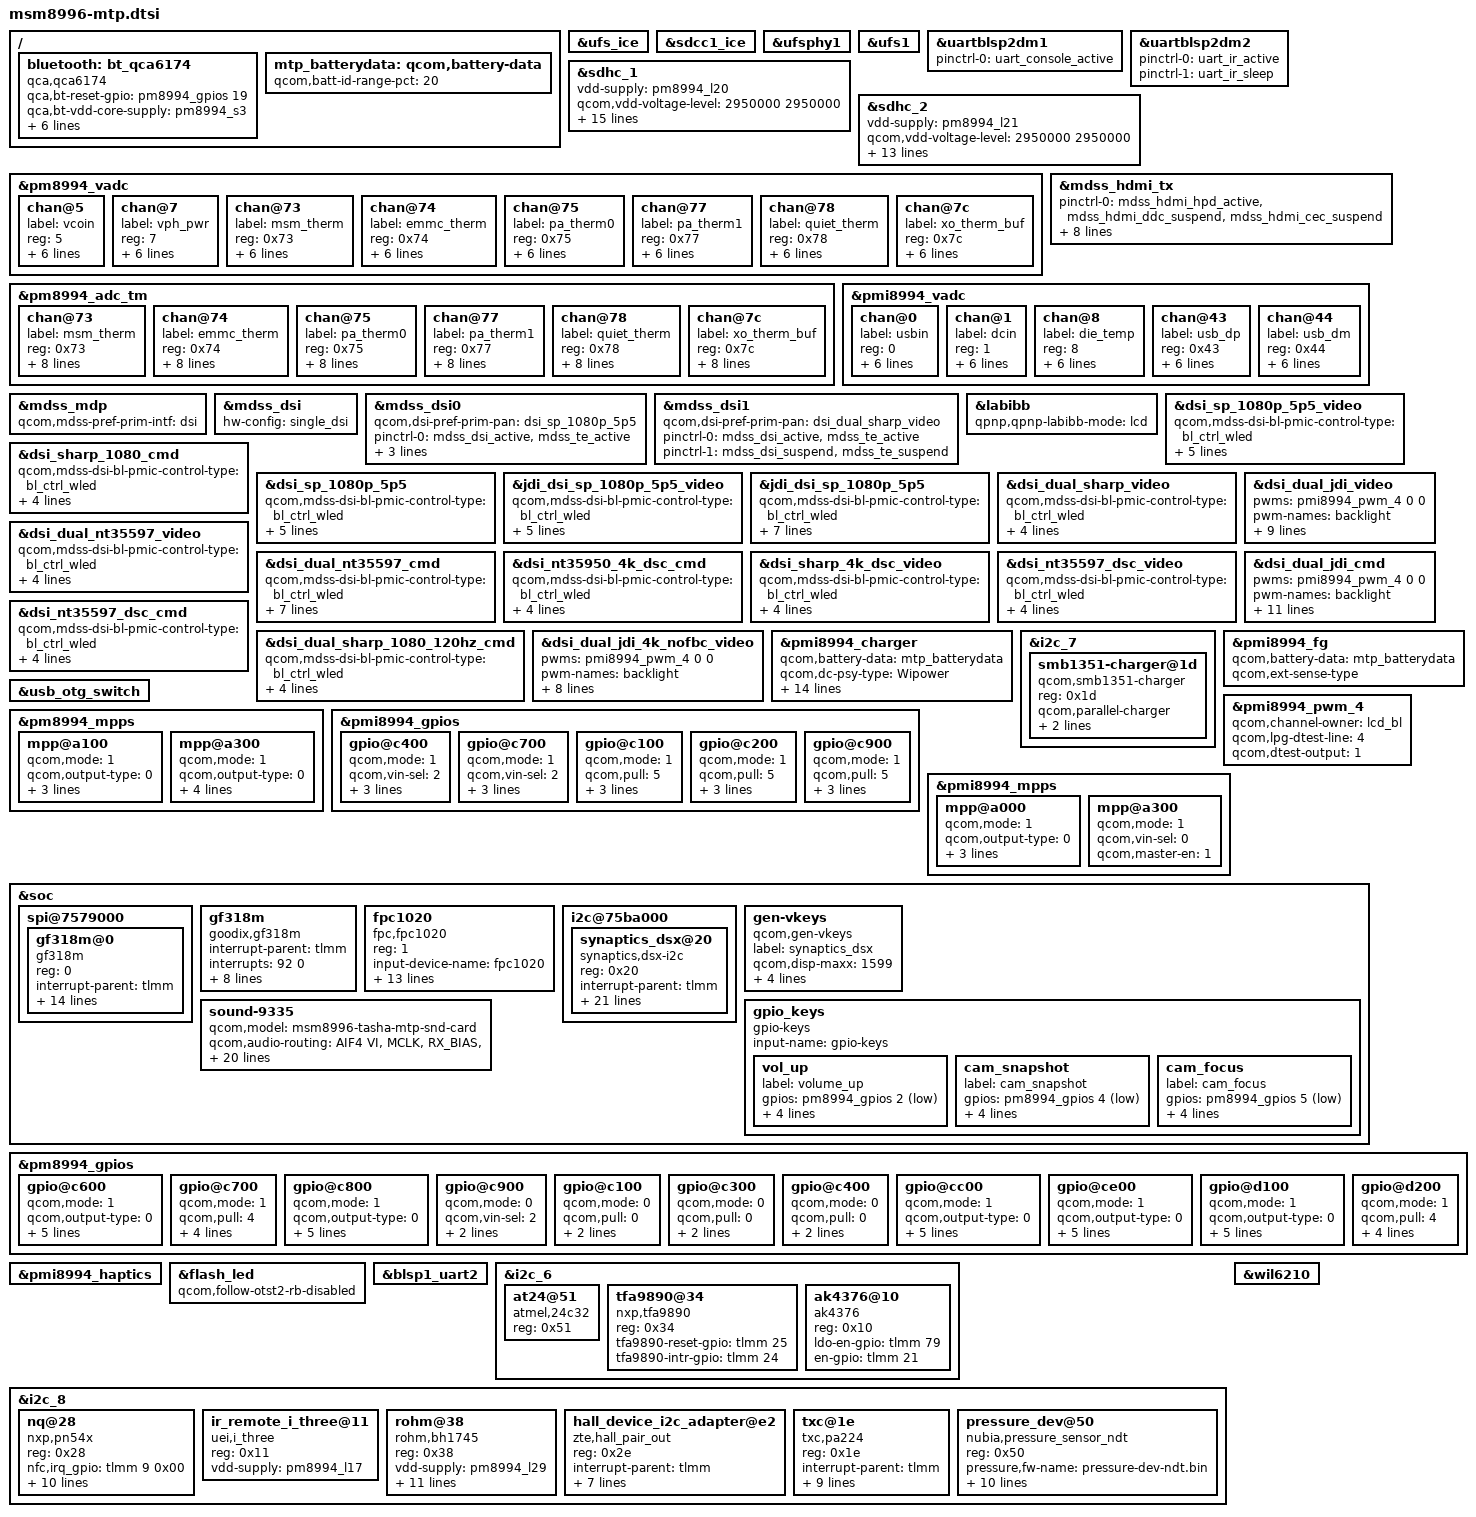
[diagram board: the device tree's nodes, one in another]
/* Copyright (c) 2015-2016, The Linux Foundation. All rights reserved.
 *
 * This program is free software; you can redistribute it and/or modify
 * it under the terms of the GNU General Public License version 2 and
 * only version 2 as published by the Free Software Foundation.
 *
 * This program is distributed in the hope that it will be useful,
 * but WITHOUT ANY WARRANTY; without even the implied warranty of
 * MERCHANTABILITY or FITNESS FOR A PARTICULAR PURPOSE.  See the
 * GNU General Public License for more details.
 */

#include "msm8996-pinctrl.dtsi"
#include "msm8996-camera-sensor-mtp.dtsi"
#include "msm8996-mtp-typec-ctl.dtsi"

/ {
	bluetooth: bt_qca6174 {
		compatible = "qca,qca6174";
		qca,bt-reset-gpio = <&pm8994_gpios 19 0>; /* BT_EN */
		qca,bt-vdd-core-supply = <&pm8994_s3>;
		qca,bt-vdd-pa-supply = <&rome_vreg>;
		qca,bt-vdd-io-supply = <&pm8994_s4>;
		qca,bt-vdd-xtal-supply = <&pm8994_l30>;
		qca,bt-chip-pwd-voltage-level = <1300000 1300000>;
		qca,bt-vdd-io-voltage-level = <1800000 1800000>;
		qca,bt-vdd-xtal-voltage-level = <1800000 1800000>;
	};
};

&ufs_ice {
        status = "ok";
};

&sdcc1_ice {
        status = "ok";
};

&ufsphy1 {
	status = "ok";
};

&ufs1 {
	status = "ok";
};

&uartblsp2dm1 {
	status = "ok";
	pinctrl-names = "default";
	pinctrl-0 = <&uart_console_active>;
};
&uartblsp2dm2 {
	status = "ok";
	pinctrl-names = "default","sleep";
	pinctrl-0 = <&uart_ir_active>;
	pinctrl-1 = <&uart_ir_sleep>;
};
&sdhc_1 {
	vdd-supply = <&pm8994_l20>;
	qcom,vdd-voltage-level = <2950000 2950000>;
	qcom,vdd-current-level = <200 570000>;

	vdd-io-supply = <&pm8994_s4>;
	qcom,vdd-io-always-on;
	qcom,vdd-io-voltage-level = <1800000 1800000>;
	qcom,vdd-io-current-level = <110 325000>;

	pinctrl-names = "active", "sleep";
	pinctrl-0 = <&sdc1_clk_on &sdc1_cmd_on &sdc1_data_on &sdc1_rclk_on>;
	pinctrl-1 = <&sdc1_clk_off &sdc1_cmd_off &sdc1_data_off &sdc1_rclk_off>;

	qcom,clk-rates = <400000 20000000 25000000 50000000 96000000 192000000 384000000>;
	qcom,ice-clk-rates = <300000000 150000000>;
	qcom,nonremovable;
	qcom,bus-speed-mode = "HS400_1p8v", "HS200_1p8v", "DDR_1p8v";

	status = "ok";
};

&sdhc_2 {
	vdd-supply = <&pm8994_l21>;
	qcom,vdd-voltage-level = <2950000 2950000>;
	qcom,vdd-current-level = <200 800000>;

	vdd-io-supply = <&pm8994_l13>;
	qcom,vdd-io-voltage-level = <1800000 2950000>;
	qcom,vdd-io-current-level = <200 22000>;

	pinctrl-names = "active", "sleep";
	pinctrl-0 = <&sdc2_clk_on  &sdc2_cmd_on &sdc2_data_on &sdc2_cd_on>;
	pinctrl-1 = <&sdc2_clk_off &sdc2_cmd_off &sdc2_data_off &sdc2_cd_off>;

	qcom,clk-rates = <400000 20000000 25000000 50000000 100000000 200000000>;
	qcom,bus-speed-mode = "SDR12", "SDR25", "SDR50", "DDR50", "SDR104";

	cd-gpios = <&tlmm 95 0x0>;

	status = "ok";
};

&pm8994_vadc {
	chan@5 {
		label = "vcoin";
		reg = <5>;
		qcom,decimation = <0>;
		qcom,pre-div-channel-scaling = <1>;
		qcom,calibration-type = "absolute";
		qcom,scale-function = <0>;
		qcom,hw-settle-time = <0>;
		qcom,fast-avg-setup = <0>;
	};

	chan@7 {
		label = "vph_pwr";
		reg = <7>;
		qcom,decimation = <0>;
		qcom,pre-div-channel-scaling = <1>;
		qcom,calibration-type = "absolute";
		qcom,scale-function = <0>;
		qcom,hw-settle-time = <0>;
		qcom,fast-avg-setup = <0>;
	};

	chan@73 {
		label = "msm_therm";
		reg = <0x73>;
		qcom,decimation = <0>;
		qcom,pre-div-channel-scaling = <0>;
		qcom,calibration-type = "ratiometric";
		qcom,scale-function = <2>;
		qcom,hw-settle-time = <2>;
		qcom,fast-avg-setup = <0>;
	};

	chan@74 {
		label = "emmc_therm";
		reg = <0x74>;
		qcom,decimation = <0>;
		qcom,pre-div-channel-scaling = <0>;
		qcom,calibration-type = "ratiometric";
		qcom,scale-function = <2>;
		qcom,hw-settle-time = <2>;
		qcom,fast-avg-setup = <0>;
	};

	chan@75 {
		label = "pa_therm0";
		reg = <0x75>;
		qcom,decimation = <0>;
		qcom,pre-div-channel-scaling = <0>;
		qcom,calibration-type = "ratiometric";
		qcom,scale-function = <2>;
		qcom,hw-settle-time = <2>;
		qcom,fast-avg-setup = <0>;
	};

	chan@77 {
		label = "pa_therm1";
		reg = <0x77>;
		qcom,decimation = <0>;
		qcom,pre-div-channel-scaling = <0>;
		qcom,calibration-type = "ratiometric";
		qcom,scale-function = <2>;
		qcom,hw-settle-time = <2>;
		qcom,fast-avg-setup = <0>;
	};

	chan@78 {
		label = "quiet_therm";
		reg = <0x78>;
		qcom,decimation = <0>;
		qcom,pre-div-channel-scaling = <0>;
		qcom,calibration-type = "ratiometric";
		qcom,scale-function = <2>;
		qcom,hw-settle-time = <2>;
		qcom,fast-avg-setup = <0>;
	};

	chan@7c {
		label = "xo_therm_buf";
		reg = <0x7c>;
		qcom,decimation = <0>;
		qcom,pre-div-channel-scaling = <0>;
		qcom,calibration-type = "ratiometric";
		qcom,scale-function = <4>;
		qcom,hw-settle-time = <2>;
		qcom,fast-avg-setup = <0>;
	};

	chan@7c {
		label = "xo_therm_buf";
		reg = <0x7c>;
		qcom,decimation = <0>;
		qcom,pre-div-channel-scaling = <0>;
		qcom,calibration-type = "ratiometric";
		qcom,scale-function = <4>;
		qcom,hw-settle-time = <2>;
		qcom,fast-avg-setup = <0>;
	};
};

&pm8994_adc_tm {
	chan@73 {
		label = "msm_therm";
		reg = <0x73>;
		qcom,decimation = <0>;
		qcom,pre-div-channel-scaling = <0>;
		qcom,calibration-type = "ratiometric";
		qcom,scale-function = <2>;
		qcom,hw-settle-time = <2>;
		qcom,fast-avg-setup = <0>;
		qcom,btm-channel-number = <0x48>;
		qcom,thermal-node;
	};

	chan@74 {
		label = "emmc_therm";
		reg = <0x74>;
		qcom,decimation = <0>;
		qcom,pre-div-channel-scaling = <0>;
		qcom,calibration-type = "ratiometric";
		qcom,scale-function = <2>;
		qcom,hw-settle-time = <2>;
		qcom,fast-avg-setup = <0>;
		qcom,btm-channel-number = <0x68>;
		qcom,thermal-node;
	};

	chan@75 {
		label = "pa_therm0";
		reg = <0x75>;
		qcom,decimation = <0>;
		qcom,pre-div-channel-scaling = <0>;
		qcom,calibration-type = "ratiometric";
		qcom,scale-function = <2>;
		qcom,hw-settle-time = <2>;
		qcom,fast-avg-setup = <0>;
		qcom,btm-channel-number = <0x70>;
		qcom,thermal-node;
	};

	chan@77 {
		label = "pa_therm1";
		reg = <0x77>;
		qcom,decimation = <0>;
		qcom,pre-div-channel-scaling = <0>;
		qcom,calibration-type = "ratiometric";
		qcom,scale-function = <2>;
		qcom,hw-settle-time = <2>;
		qcom,fast-avg-setup = <0>;
		qcom,btm-channel-number = <0x78>;
		qcom,thermal-node;
	};

	chan@78 {
		label = "quiet_therm";
		reg = <0x78>;
		qcom,decimation = <0>;
		qcom,pre-div-channel-scaling = <0>;
		qcom,calibration-type = "ratiometric";
		qcom,scale-function = <2>;
		qcom,hw-settle-time = <2>;
		qcom,fast-avg-setup = <0>;
		qcom,btm-channel-number = <0x80>;
		qcom,thermal-node;
	};

	chan@7c {
		label = "xo_therm_buf";
		reg = <0x7c>;
		qcom,decimation = <0>;
		qcom,pre-div-channel-scaling = <0>;
		qcom,calibration-type = "ratiometric";
		qcom,scale-function = <4>;
		qcom,hw-settle-time = <2>;
		qcom,fast-avg-setup = <0>;
		qcom,btm-channel-number = <0x88>;
		qcom,thermal-node;
	};
};

&mdss_hdmi_tx {
	pinctrl-names = "hdmi_hpd_active", "hdmi_ddc_active", "hdmi_cec_active",
				"hdmi_active", "hdmi_sleep";
	pinctrl-0 = <&mdss_hdmi_hpd_active &mdss_hdmi_ddc_suspend
						&mdss_hdmi_cec_suspend>;
	pinctrl-1 = <&mdss_hdmi_hpd_active &mdss_hdmi_ddc_active
						&mdss_hdmi_cec_suspend>;
	pinctrl-2 = <&mdss_hdmi_hpd_active &mdss_hdmi_cec_active
						&mdss_hdmi_ddc_suspend>;
	pinctrl-3 = <&mdss_hdmi_hpd_active &mdss_hdmi_ddc_active
						&mdss_hdmi_cec_active>;
	pinctrl-4 = <&mdss_hdmi_hpd_suspend &mdss_hdmi_ddc_suspend
						&mdss_hdmi_cec_suspend>;
};

&pmi8994_vadc {
	chan@0 {
		label = "usbin";
		reg = <0>;
		qcom,decimation = <0>;
		qcom,pre-div-channel-scaling = <4>;
		qcom,calibration-type = "absolute";
		qcom,scale-function = <0>;
		qcom,hw-settle-time = <0>;
		qcom,fast-avg-setup = <0>;
	};

	chan@1 {
		label = "dcin";
		reg = <1>;
		qcom,decimation = <0>;
		qcom,pre-div-channel-scaling = <4>;
		qcom,calibration-type = "absolute";
		qcom,scale-function = <0>;
		qcom,hw-settle-time = <0>;
		qcom,fast-avg-setup = <0>;
	};

	/*CONFIG_ZTEMT_MSM8996_CHARGER*/
	chan@8 {
		label = "die_temp";
		reg = <8>;
		qcom,decimation = <0>;
		qcom,pre-div-channel-scaling = <0>;
		qcom,calibration-type = "absolute";
		qcom,scale-function = <3>;
		qcom,hw-settle-time = <0>;
		qcom,fast-avg-setup = <0>;
	};

	chan@43 {
		label = "usb_dp";
		reg = <0x43>;
		qcom,decimation = <0>;
		qcom,pre-div-channel-scaling = <1>;
		qcom,calibration-type = "absolute";
		qcom,scale-function = <0>;
		qcom,hw-settle-time = <0>;
		qcom,fast-avg-setup = <0>;
	};

	chan@44 {
		label = "usb_dm";
		reg = <0x44>;
		qcom,decimation = <0>;
		qcom,pre-div-channel-scaling = <1>;
		qcom,calibration-type = "absolute";
		qcom,scale-function = <0>;
		qcom,hw-settle-time = <0>;
		qcom,fast-avg-setup = <0>;
	};
};

#include "../msm8996-mdss-panels.dtsi"

&mdss_mdp {
	qcom,mdss-pref-prim-intf = "dsi";
};

&mdss_dsi {
	hw-config = "single_dsi";
};

&mdss_dsi0 {
	qcom,dsi-pref-prim-pan = <&dsi_sp_1080p_5p5>;
	pinctrl-names = "mdss_default", "mdss_sleep";
	pinctrl-0 = <&mdss_dsi_active &mdss_te_active>;
	pinctrl-1 = <&mdss_dsi_suspend &mdss_te_suspend>;
	qcom,platform-te-gpio = <&tlmm 10 0>;
	qcom,platform-reset-gpio = <&tlmm 8 0>;
	//qcom,platform-bklight-en-gpio = <&pm8994_gpios 14 0>; //ZTEMT: guxiaodong comment out pm8994_gpios 14
};

&mdss_dsi1 {
	qcom,dsi-pref-prim-pan = <&dsi_dual_sharp_video>;
	pinctrl-names = "mdss_default", "mdss_sleep";
	pinctrl-0 = <&mdss_dsi_active &mdss_te_active>;
	pinctrl-1 = <&mdss_dsi_suspend &mdss_te_suspend>;
};

&labibb {
	status = "ok";
	qpnp,qpnp-labibb-mode = "lcd";
};

&dsi_sp_1080p_5p5_video {
        qcom,mdss-dsi-bl-pmic-control-type = "bl_ctrl_wled";
        qcom,mdss-dsi-bl-min-level = <1>;
        qcom,mdss-dsi-bl-max-level = <4095>;
        qcom,cont-splash-enabled;
        qcom,panel-supply-entries = <&dsi_panel_pwr_supply>;
};

&dsi_sharp_1080_cmd {
	qcom,mdss-dsi-bl-pmic-control-type = "bl_ctrl_wled";
	qcom,mdss-dsi-bl-min-level = <1>;
	qcom,mdss-dsi-bl-max-level = <4095>;
	qcom,panel-supply-entries = <&dsi_panel_pwr_supply>;
};

&dsi_sp_1080p_5p5 {
	qcom,mdss-dsi-bl-pmic-control-type = "bl_ctrl_wled";
	qcom,mdss-dsi-bl-min-level = <1>;
	qcom,mdss-dsi-bl-max-level = <4095>;
	qcom,cont-splash-enabled;
	qcom,panel-supply-entries = <&dsi_panel_pwr_supply>;
};

&jdi_dsi_sp_1080p_5p5_video {
        qcom,mdss-dsi-bl-pmic-control-type = "bl_ctrl_wled";
        qcom,mdss-dsi-bl-min-level = <1>;
        qcom,mdss-dsi-bl-max-level = <4095>;
        qcom,cont-splash-enabled;
        qcom,panel-supply-entries = <&dsi_panel_pwr_supply>;
};

&jdi_dsi_sp_1080p_5p5 {
	qcom,mdss-dsi-bl-pmic-control-type = "bl_ctrl_wled";
	qcom,mdss-dsi-bl-min-level = <35>;
	qcom,mdss-dsi-bl-max-level = <3677>;
	nubia,disable-dimming-when-suspend;
	nubia,enable-dimming-when-resume;
	qcom,cont-splash-enabled;
	qcom,panel-supply-entries = <&dsi_panel_pwr_supply>;
};


&dsi_dual_sharp_video {
	qcom,mdss-dsi-bl-pmic-control-type = "bl_ctrl_wled";
	qcom,mdss-dsi-bl-min-level = <1>;
	qcom,mdss-dsi-bl-max-level = <4095>;
	qcom,panel-supply-entries = <&dsi_panel_pwr_supply>;
};

&dsi_dual_nt35597_video {
	qcom,mdss-dsi-bl-pmic-control-type = "bl_ctrl_wled";
	qcom,mdss-dsi-bl-min-level = <1>;
	qcom,mdss-dsi-bl-max-level = <4095>;
	qcom,panel-supply-entries = <&dsi_panel_pwr_supply>;
};

&dsi_dual_nt35597_cmd {
	qcom,mdss-dsi-bl-pmic-control-type = "bl_ctrl_wled";
	qcom,mdss-dsi-bl-min-level = <1>;
	qcom,mdss-dsi-bl-max-level = <4095>;
	qcom,panel-supply-entries = <&dsi_panel_pwr_supply>;
	qcom,partial-update-enabled;
	qcom,panel-roi-alignment = <720 128 720 64 720 64>;
};

&dsi_nt35950_4k_dsc_cmd {
	qcom,mdss-dsi-bl-pmic-control-type = "bl_ctrl_wled";
	qcom,mdss-dsi-bl-min-level = <1>;
	qcom,mdss-dsi-bl-max-level = <4095>;
	qcom,panel-supply-entries = <&dsi_panel_pwr_supply>;
};

&dsi_sharp_4k_dsc_video {
	qcom,mdss-dsi-bl-pmic-control-type = "bl_ctrl_wled";
	qcom,mdss-dsi-bl-min-level = <1>;
	qcom,mdss-dsi-bl-max-level = <4095>;
	qcom,panel-supply-entries = <&dsi_panel_pwr_supply>;
};

&dsi_nt35597_dsc_video {
	qcom,mdss-dsi-bl-pmic-control-type = "bl_ctrl_wled";
	qcom,mdss-dsi-bl-min-level = <1>;
	qcom,mdss-dsi-bl-max-level = <4095>;
	qcom,panel-supply-entries = <&dsi_panel_pwr_supply>;
};

&dsi_nt35597_dsc_cmd {
	qcom,mdss-dsi-bl-pmic-control-type = "bl_ctrl_wled";
	qcom,mdss-dsi-bl-min-level = <1>;
	qcom,mdss-dsi-bl-max-level = <4095>;
	qcom,panel-supply-entries = <&dsi_panel_pwr_supply>;
};

&dsi_dual_sharp_1080_120hz_cmd {
	qcom,mdss-dsi-bl-pmic-control-type = "bl_ctrl_wled";
	qcom,mdss-dsi-bl-min-level = <1>;
	qcom,mdss-dsi-bl-max-level = <4095>;
	qcom,panel-supply-entries = <&dsi_panel_pwr_supply>;
};

&dsi_dual_jdi_video {
	pwms = <&pmi8994_pwm_4 0 0>;
	pwm-names = "backlight";
	qcom,mdss-dsi-bl-pmic-control-type = "bl_ctrl_pwm";
	qcom,mdss-dsi-bl-pwm-pmi;
	qcom,mdss-dsi-bl-pmic-pwm-frequency = <100>;
	qcom,mdss-dsi-bl-min-level = <1>;
	qcom,mdss-dsi-bl-max-level = <4095>;
	qcom,5v-boost-gpio = <&pmi8994_gpios 8 0>;
	qcom,panel-supply-entries = <&dsi_panel_pwr_supply>;
};

&dsi_dual_jdi_cmd {
	pwms = <&pmi8994_pwm_4 0 0>;
	pwm-names = "backlight";
	qcom,mdss-dsi-bl-pmic-control-type = "bl_ctrl_pwm";
	qcom,mdss-dsi-bl-pwm-pmi;
	qcom,mdss-dsi-bl-pmic-pwm-frequency = <100>;
	qcom,mdss-dsi-bl-min-level = <1>;
	qcom,mdss-dsi-bl-max-level = <4095>;
	qcom,5v-boost-gpio = <&pmi8994_gpios 8 0>;
	qcom,panel-supply-entries = <&dsi_panel_pwr_supply>;
	qcom,partial-update-enabled;
	qcom,panel-roi-alignment = <4 4 2 2 20 20>;
};

&dsi_dual_jdi_4k_nofbc_video {
	pwms = <&pmi8994_pwm_4 0 0>;
	pwm-names = "backlight";
	qcom,mdss-dsi-bl-pmic-control-type = "bl_ctrl_pwm";
	qcom,mdss-dsi-bl-pwm-pmi;
	qcom,mdss-dsi-bl-pmic-pwm-frequency = <100>;
	qcom,mdss-dsi-bl-min-level = <1>;
	qcom,mdss-dsi-bl-max-level = <4095>;
	qcom,panel-supply-entries = <&dsi_panel_pwr_supply>;
};

/{
	mtp_batterydata: qcom,battery-data {
		qcom,batt-id-range-pct = <20>;//ZTEMT modified from 15 to 20
		//#include "../batterydata-itech-3000mah.dtsi"
		#include "batterydata-ztemt-4v4-3000mah.dtsi"
	};
};

&pmi8994_charger {
	/*ZTEMT Add*/
	qcom,battery-data = <&mtp_batterydata>;
	qcom,dc-psy-type = "Wipower";
	qcom,dcin-vadc = <&pmi8994_vadc>;
	qcom,wipower-default-ilim-map = <4000000 20000000 550 700 300>;
	qcom,wipower-pt-ilim-map = <4000000 7140000 550 700 300>,
					<7140000 8140000 550 700 300>,
					<8140000 9140000 500 700 300>,
					<9140000 9950000 500 700 300>;
	qcom,wipower-div2-ilim-map = <4000000 4820000 550 700 300>,
					<4820000 5820000 550 700 300>,
					<5820000 6820000 550 650 650>,
					<6820000 7820000 550 700 600>,
					<7820000 8500000 550 700 550>;
};

&i2c_7 {
	smb1351-charger@1d {
		compatible = "qcom,smb1351-charger";
		reg = <0x1d>;
		qcom,parallel-charger;
		qcom,float-voltage-mv = <4400>;
		qcom,recharge-mv = <100>;
	};
};

&pmi8994_fg {
	qcom,battery-data = <&mtp_batterydata>;
	qcom,ext-sense-type;
};

&usb_otg_switch {
	status = "okay";
};

&pm8994_mpps {
	mpp@a100 { /* MPP 2 */
		qcom,mode = <1>;		/* Digital output */
		qcom,output-type = <0>;		/* CMOS logic */
		qcom,vin-sel = <2>;		/* S4 1.8V */
		qcom,src-sel = <0>;		/* Constant */
		qcom,master-en = <1>;		/* Enable GPIO */
		status = "okay";
	};

	mpp@a300 { /* MPP 4 */
		/* HDMI_5v_vreg regulator enable */
		qcom,mode = <1>;		/* Digital output */
		qcom,output-type = <0>;		/* CMOS logic */
		qcom,vin-sel = <2>;		/* S4 1.8V */
		qcom,src-sel = <0>;		/* Constant */
		qcom,master-en = <1>;		/* Enable GPIO */
		qcom,invert = <0>;
		status = "okay";
	};
};

&pmi8994_gpios {
	gpio@c400 { /* GPIO 5 - USB3 OTG SWITCH EN */
		qcom,mode = <1>;	/* Digital output */
		qcom,vin-sel = <2>;	/* 1.8 */
		qcom,src-sel = <0>;	/* GPIO */
		qcom,master-en = <1>;	/* Enable GPIO */
		qcom,invert = <0>;	/* Output low initially */
		status = "okay";
	};
};

&pmi8994_gpios {
	gpio@c700 {	/* GPIO 8, lcd_reg_en, 5V boost  */
		qcom,mode = <1>;
		qcom,vin-sel = <2>;
		qcom,src-sel = <0>;
		qcom,invert = <1>;   /* need invert = 0 */
		qcom,master-en = <1>;
		status = "okay";
	};

	gpio@c100 {	/* GPIO 2  SPKR_SD_N */
		qcom,mode = <1>;	/* DIGITAL OUT */
		qcom,pull = <5>;	/* No Pull */
		qcom,vin-sel = <2>;	/* 1.8 */
		qcom,src-sel = <0>;	/* CONSTANT */
		qcom,master-en = <1>;	/* ENABLE GPIO */
		status = "okay";
	};

	gpio@c200 {	/* GPIO 3 SPKR_SD_N */
		qcom,mode = <1>;	/* DIGITAL OUT */
		qcom,pull = <5>;	/* No Pull */
		qcom,vin-sel = <2>;	/* 1.8 */
		qcom,src-sel = <0>;	/* CONSTANT */
		qcom,master-en = <1>;	/* ENABLE GPIO */
		status = "okay";
	};

	gpio@c900 { /* GPIO 10 - HPH_EN1 */
		qcom,mode = <1>;
		qcom,pull = <5>;
		qcom,vin-sel = <2>;
		qcom,src-sel = <2>;
		qcom,master-en = <1>;
		status = "okay";
	};
};

&pmi8994_pwm_4 {
	qcom,channel-owner = "lcd_bl";
	qcom,lpg-dtest-line = <4>;
	qcom,dtest-output = <1>;
	status = "okay";
};

&pmi8994_mpps {
	mpp@a000 { /* MPP 1 */
		qcom,mode = <1>;                /* Digital output */
		qcom,output-type = <0>;         /* CMOS logic */
		qcom,vin-sel = <2>;             /* S4 1.8V */
		qcom,src-sel = <7>;             /* DTEST4 */
		qcom,master-en = <1>;           /* Enable MPP */
		status = "okay";
	};

	mpp@a300 { /* MPP 4 */
		/* WLED FET */
		qcom,mode = <1>;        /* DIGITAL OUT */
		qcom,vin-sel = <0>;     /* VIN0 */
		qcom,master-en = <1>;
		status = "okay";
	};
};

&soc {
	// nubia add start
	// add goodix fingerprint as spi device
	spi@7579000 {
		gf318m@0{
			status = "ok";
			compatible = "gf318m";
			reg = <0>;
			interrupt-parent = <&tlmm>;
			interrupts = <92 0>;
			gf-gpio-rst  = <&tlmm 93 0x00>;
			gf-gpio-drdy = <&tlmm 92 0x00>;
			gf-gpio-enable = <&tlmm 63 0x00>;

			pinctrl-names = "gf_active", "gf_suspend", "gf_int_active";
			pinctrl-0 = <&fp_drdy_active &fp_rst_active &fp_enable_active>;
			pinctrl-1 = <&fp_drdy_suspend &fp_rst_suspend &fp_enable_suspend>;
			pinctrl-2 = <&fp_drdy_active>;
			spi-max-frequency = <4800000>;
			qcom,qup-id = <1>;
			clock-names = "iface_clk", "core_clk";
			clocks = <&clock_gcc clk_gcc_blsp1_ahb_clk>,
					 <&clock_gcc clk_gcc_blsp1_qup5_spi_apps_clk>;
			gf,tz-enable;
		};
	};

	// add goodix fingerprint as platform device
	gf318m {
		status = "ok";
		compatible = "goodix,gf318m";
		interrupt-parent = <&tlmm>;
		interrupts = <92 0>;
		gf-gpio-rst  = <&tlmm 93 0x00>;
		gf-gpio-drdy = <&tlmm 92 0x00>;
		gf-gpio-enable = <&tlmm 63 0x00>;

		pinctrl-names = "gf_active", "gf_suspend", "gf_int_active";
		pinctrl-0 = <&fp_drdy_active &fp_rst_active &fp_enable_active>;
		pinctrl-1 = <&fp_drdy_suspend &fp_rst_suspend &fp_enable_suspend>;
		pinctrl-2 = <&fp_drdy_active>;
	};

	// add fpc fingerprint as platform device
	fpc1020{
		status = "ok";
		reg = <1>;
		compatible = "fpc,fpc1020";
		input-device-name = "fpc1020";
		interrupt-parent = <&tlmm>;
		interrupts = <92 0>;
		fpc,reset-gpio    = <&tlmm 93 0x00>;
		fpc,irq-gpio    = <&tlmm 92 0x00>;
		fpc,enable-gpio = <&tlmm 63 0x00>;

		pinctrl-names = "pmx_fp_active", "pmx_fp_suspend";
		pinctrl-0 = <&fp_drdy_active &fp_rst_active &fp_enable_active>;
		pinctrl-1 = <&fp_drdy_suspend &fp_rst_suspend &fp_enable_suspend>;

		spi-max-frequency = <4800000>;
		spi-qup-id = <1>;
		clock-names = "iface_clk", "core_clk";
		clocks = <&clock_gcc clk_gcc_blsp1_ahb_clk>,
			     <&clock_gcc clk_gcc_blsp1_qup5_spi_apps_clk>;
	};
	// nubia add end

	i2c@75ba000 {
#if 0
		synaptics@20 {
			compatible = "synaptics,dsx";
			reg = <0x20>;
			interrupt-parent = <&tlmm>;
			interrupts = <125 0x2008>;
			vdd-supply = <&pm8994_l18>;
			avdd-supply = <&pm8994_l22>;
			pinctrl-names = "pmx_ts_active", "pmx_ts_suspend";
			pinctrl-0 = <&ts_active>;
			pinctrl-1 = <&ts_suspend>;
			synaptics,display-coords = <0 0 1599 2559>;
			synaptics,panel-coords = <0 0 1599 2703>;
			synaptics,reset-gpio = <&tlmm 89 0x00>;
			synaptics,irq-gpio = <&tlmm 125 0x2008>;
			synaptics,disable-gpios;
			synaptics,fw-name = "PR1702898-s3528t_00350002.img";
			/* Underlying clocks used by secure touch */
			clock-names = "iface_clk", "core_clk";
			clocks = <&clock_gcc clk_gcc_blsp2_ahb_clk>,
				 <&clock_gcc clk_gcc_blsp2_qup6_i2c_apps_clk>;
		};
#endif

	synaptics_dsx@20 {
		compatible = "synaptics,dsx-i2c";
		reg = <0x20>;
		interrupt-parent = <&tlmm>;
		interrupts = <125 0x2008>;
		vdd_ana-supply = <&pm8994_l22>;
		vcc_i2c-supply = <&pm8994_l18>;
		vcc_i2c_MB_A-supply = <&pm8994_l14>;
		synaptics,pwr-reg-name = "vdd_ana";
		synaptics,bus-reg-name = "vcc_i2c";
		synaptics,bus-reg-name-MB-A = "vcc_i2c_MB_A";
		synaptics,irq-gpio = <&tlmm 125 0x2008>;
		synaptics,irq-on-state = <0>;
		synaptics,irq-flags = <0x2008>; /* IRQF_ONESHOT | IRQF_TRIGGER_LOW */
		synaptics,power-delay-ms = <200>;
		synaptics,reset-gpio = <&tlmm 89 0x0>;
		synaptics,reset-on-state = <0>;
		synaptics,reset-active-ms = <20>;
		synaptics,reset-delay-ms = <20>;
		synaptics,lcd-reset-gpio = <&tlmm 8 0x0>;
		synaptics,cap-button-codes = <172 139 158>;
		pinctrl-names = "synaptics_pin_active", "synaptics_pin_suspend";
		pinctrl-0 = <&synaptics_int_active &synaptics_reset_active>;
		pinctrl-1 = <&synaptics_int_suspend &synaptics_reset_suspend>;
	};

#if 0
		cyttsp_i2c_adapter@24 {
			compatible = "cy,cyttsp5_i2c_adapter";
			reg = <0x24>;
			interrupt-parent = <&tlmm>;
			interrupts = <125 0x2008>;
			cy,adapter_id = "cyttsp5_i2c_adapter";
			vdd_ana-supply = <&pm8994_l22>;
			vcc_i2c-supply = <&pm8994_l18>;
			//vcc_i2c-supply = <&pm8994_s4>;
			pinctrl-names = "cyttsp5_pin_active", "cyttsp5_pin_suspend";
			pinctrl-0 = <&ts_active>;
			pinctrl-1 = <&ts_suspend>;
			cy,core {
				cy,name = "cyttsp5_core";
				cy,irq_gpio = <&tlmm 125 0x2008>;
				cy,rst_gpio = <&tlmm 89 0x00>;
				cy,hid_desc_register = <1>;
				/* CY_CORE_FLAG_WAKE_ON_GESTURE | CY_CORE_FLAG_RESTORE_PARAMETERS */
				cy,flags = <0x05>;
				/* CY_CORE_EWG_NONE */
				cy,easy_wakeup_gesture = <0>;
				cy,btn_keys = <139	/* KEY_MENU */
				          172 /* KEY_HOMEPAGE */
					       158>;	/* KEY_BACK */
				cy,btn_keys-tag = <0>;

				cy,mt {
					cy,name = "cyttsp5_mt";
					cy,inp_dev_name = "cyttsp5_mt";
					cy,flags = <0x00>;
					cy,abs =
						/* ABS_MT_POSITION_X, CY_ABS_MIN_X, CY_ABS_MAX_X, 0, 0 */
						<0x35 0 1080 0 0
						/* ABS_MT_POSITION_Y, CY_ABS_MIN_Y, CY_ABS_MAX_Y, 0, 0 */
						0x36 0 1920 0 0
						/* ABS_MT_PRESSURE, CY_ABS_MIN_P, CY_ABS_MAX_P, 0, 0 */
						0x3a 0 255 0 0
						/* CY_IGNORE_VALUE, CY_ABS_MIN_W, CY_ABS_MAX_W, 0, 0 */
						0xffff 0 255 0 0
						/* ABS_MT_TRACKING_ID, CY_ABS_MIN_T, CY_ABS_MAX_T, 0, 0 */
						0x39 0 15 0 0
						/* ABS_MT_TOUCH_MAJOR, 0, 255, 0, 0 */
						0x30 0 255 0 0
						/* ABS_MT_TOUCH_MINOR, 0, 255, 0, 0 */
						0x31 0 255 0 0
						/* ABS_MT_ORIENTATION, -127, 127, 0, 0 */
						0x34 0xffffff81 127 0 0
						/* ABS_MT_TOOL_TYPE, 0, MT_TOOL_MAX, 0, 0 */
						/* 0x37 0 1 0 0 */
						/* ABS_DISTANCE, 0, 255, 0, 0 */
						0x19 0 255 0 0>;

					cy,vkeys_x = <1080>;
					cy,vkeys_y = <1920>;

					cy,virtual_keys = /* KeyCode CenterX CenterY Width Height */
						/* KEY_BACK */
						<158 1360 90 160 180
						/* KEY_MENU */
						139 1360 270 160 180
						/* KEY_HOMEPAGE */
						172 1360 450 160 180
						/* KEY SEARCH */
						217 1360 630 160 180>;
				};

				cy,btn {
					cy,name = "cyttsp5_btn";
					cy,inp_dev_name = "cyttsp5_btn";
				};
			};
		};
		gt1x@5d {
			compatible = "goodix,gt1x";
			reg = <0x5d>;
			interrupt-parent = <&tlmm>;
			interrupts = <125 0x2008>;
			vdd_ana-supply = <&pm8994_l22>;
			vcc_i2c-supply = <&pm8994_l18>;
			//vcc_i2c-supply = <&pm8994_s4>;
			pinctrl-names = "gt1x_int_default", "gt1x_int_sleep";
			pinctrl-0 = <&ts_active>;
			pinctrl-1 = <&ts_suspend>;
			goodix,reset-gpio = <&tlmm 89 0x00>;
			goodix,irq-gpio = <&tlmm 125 0x2008>;
		};
#endif

	};

	gen-vkeys {
		compatible = "qcom,gen-vkeys";
		label = "synaptics_dsx";
		qcom,disp-maxx = <1599>;
		qcom,disp-maxy = <2559>;
		qcom,panel-maxx = <1599>;
		qcom,panel-maxy = <2703>;
		qcom,key-codes = <158 139 102 217>;
	};

	gpio_keys {
		compatible = "gpio-keys";
		input-name = "gpio-keys";

		vol_up {
			label = "volume_up";
			gpios = <&pm8994_gpios 2 0x1>;
			linux,input-type = <1>;
			linux,code = <115>;
			gpio-key,wakeup;
			debounce-interval = <15>;
		};

		cam_snapshot {
			label = "cam_snapshot";
			gpios = <&pm8994_gpios 4 0x1>;
			linux,input-type = <1>;
			linux,code = <766>;
			gpio-key,wakeup;
			debounce-interval = <15>;
		};

		cam_focus {
			label = "cam_focus";
			gpios = <&pm8994_gpios 5 0x1>;
			linux,input-type = <1>;
			linux,code = <528>;
			gpio-key,wakeup;
			debounce-interval = <15>;
		};
	};

	sound-9335 {
		qcom,model = "msm8996-tasha-mtp-snd-card";

		qcom,audio-routing =
			"AIF4 VI", "MCLK",
			"RX_BIAS", "MCLK",
			"MADINPUT", "MCLK",
			"hifi amp", "LINEOUT1",
			"hifi amp", "LINEOUT2",
			"AMIC2", "MIC BIAS2",
			"MIC BIAS2", "Headset Mic",
			"AMIC3", "MIC BIAS2",
			"MIC BIAS2", "ANCRight Headset Mic",
			"AMIC4", "MIC BIAS2",
			"MIC BIAS2", "ANCLeft Headset Mic",
			"AMIC5", "MIC BIAS3",
			"MIC BIAS3", "Handset Mic",
			"AMIC6", "MIC BIAS4",
			"MIC BIAS4", "Analog Mic6",
			"DMIC0", "MIC BIAS1",
			"MIC BIAS1", "Digital Mic0",
			"DMIC1", "MIC BIAS1",
			"MIC BIAS1", "Digital Mic1",
			"DMIC2", "MIC BIAS3",
			"MIC BIAS3", "Digital Mic2",
			"DMIC3", "MIC BIAS3",
			"MIC BIAS3", "Digital Mic3",
			"DMIC4", "MIC BIAS4",
			"MIC BIAS4", "Digital Mic4",
			"DMIC5", "MIC BIAS4",
			"MIC BIAS4", "Digital Mic5",
			"SpkrLeft IN", "SPK1 OUT",
			"SpkrRight IN", "SPK2 OUT";

		asoc-codec = <&stub_codec>, <&hdmi_audio>;
		asoc-codec-names = "msm-stub-codec.1", "msm-hdmi-audio-codec-rx";
		qcom,hph-en1-gpio = <&pmi8994_gpios 10 0>;
		qcom,hph-en0-gpio = <&pm8994_gpios 13 0>;
	};
};

&pm8994_gpios {
	gpio@c600 { /* GPIO 7 - NFC DWL REQ */
		qcom,mode = <1>;
		qcom,output-type = <0>;
		qcom,pull = <5>;
		qcom,vin-sel = <2>;
		qcom,out-strength = <3>;
		qcom,src-sel = <0>;
		qcom,master-en = <1>;
		status = "okay";
	};

	gpio@c700 { /* GPIO 8 - WLAN_EN */
		qcom,mode = <1>;		/* Digital output*/
		qcom,pull = <4>;		/* Pulldown 10uA */
		qcom,vin-sel = <2>;		/* VIN2 */
		qcom,src-sel = <0>;		/* GPIO */
		qcom,invert = <0>;		/* Invert */
		qcom,master-en = <1>;		/* Enable GPIO */
		status = "okay";
	};

	gpio@c800 { /* GPIO 9 - Rome 3.3V control */
		qcom,mode = <1>;		/* Digital output */
		qcom,output-type = <0>;		/* MOS logic */
		qcom,invert = <1>;		/* Output high */
		qcom,vin-sel = <0>;		/* VPH_PWR */
		qcom,src-sel = <0>;		/* Constant */
		qcom,out-strength = <1>;	/* High drive strength */
		qcom,master-en = <1>;		/* Enable GPIO */
		status = "okay";
	};

	gpio@c900 { /* GPIO 10 - NFC CLK _REQ*/
		qcom,mode = <0>;
		qcom,vin-sel = <2>;
		qcom,src-sel = <0>;
		qcom,master-en = <1>;
		status = "okay";
	};
    /* ZTEMT: guxiaodong comment out pm8994_gpios 14 -------start*/
	/*gpio@cd00 { // GPIO 14 - lcd_bklt_reg_en
		qcom,mode = <1>;	// DIGITAL OUT
		qcom,output-type = <0>;		// CMOS logic
		qcom,invert = <1>; 	// output hight initially
		qcom,vin-sel = <2>;	// 1.8
		qcom,src-sel = <0>;	// CONSTANT
		qcom,out-strength = <1>;	// Low drive strength
		qcom,master-en = <1>;	// ENABLE GPIO
		status = "okay";
	};*/
    /* ZTEMT: guxiaodong comment out pm8994_gpios 14 -------end*/
	gpio@c100 { /* GPIO 2 */
		qcom,mode = <0>;
		qcom,pull = <0>;
		qcom,vin-sel = <2>;
		qcom,src-sel = <0>;
		status = "okay";
	};

	gpio@c300 { /* GPIO 4 */
		qcom,mode = <0>;
		qcom,pull = <0>;
		qcom,vin-sel = <2>;
		qcom,src-sel = <0>;
		status = "okay";
	};

	gpio@c400 { /* GPIO 5 */
		qcom,mode = <0>;
		qcom,pull = <0>;
		qcom,vin-sel = <2>;
		qcom,src-sel = <0>;
		status = "okay";
	};

	gpio@cc00 { /* GPIO 13 - HPH_EN0 */
		qcom,mode = <1>;
		qcom,output-type = <0>;
		qcom,pull = <5>;
		qcom,vin-sel = <2>;
		qcom,out-strength = <1>;
		qcom,src-sel = <2>;
		qcom,master-en = <1>;
		status = "okay";
	};

	gpio@ce00 { /* GPIO 15 */
		qcom,mode = <1>;
		qcom,output-type = <0>;
		qcom,pull = <5>;
		qcom,vin-sel = <2>;
		qcom,out-strength = <1>;
		qcom,src-sel = <2>;
		qcom,master-en = <1>;
		status = "okay";
	};

	gpio@d100 { /* GPIO 18 - Rome Sleep Clock */
		qcom,mode = <1>;		/* Digital output */
		qcom,output-type = <0>;		/* CMOS logic */
		qcom,invert = <0>;		/* Output low initially */
		qcom,vin-sel = <2>;		/* VIN 2 */
		qcom,src-sel = <3>;		/* Function 2 */
		qcom,out-strength = <2>;	/* Medium */
		qcom,master-en = <1>;		/* Enable GPIO */
		status = "okay";
	};

	gpio@d200 { /* GPIO 19 - Rome BT Reset */
		qcom,mode = <1>;		/* Digital output*/
		qcom,pull = <4>;		/* Pulldown 10uA */
		qcom,vin-sel = <2>;		/* VIN2 */
		qcom,src-sel = <0>;		/* GPIO */
		qcom,invert = <0>;		/* Invert */
		qcom,master-en = <1>;		/* Enable GPIO */
		status = "okay";
	};
};

&pmi8994_haptics {
	status = "okay";
};

&flash_led {
	qcom,follow-otst2-rb-disabled;
};

&blsp1_uart2 {
	status = "ok";
};

&i2c_6 {
	at24@51 {
		compatible = "atmel,24c32";
		reg = <0x51>;
	};
    tfa9890@34 {
        status = "ok";
        compatible = "nxp,tfa9890";
        reg =<0x34>;
        tfa9890-reset-gpio = <&tlmm 25 0x00>;
        tfa9890-intr-gpio = <&tlmm 24 0x00>;
    };

    ak4376@10 {
        status = "ok";
        compatible = "ak4376";
        reg =<0x10>;
        ldo-en-gpio = <&tlmm 79 0x00>;
        en-gpio = <&tlmm 21 0x00>;
    };
};

&i2c_7 {
/*
	silabs4705@11 { // SiLabs FM chip, slave id 0x11
		status = "ok";
		compatible = "silabs,si4705";
		reg = <0x11>;
		vdd-supply = <&pm8994_s4>;
		silabs,vdd-supply-voltage = <1800000 1800000>;
		va-supply = <&rome_vreg>;
		silabs,va-supply-voltage = <3300000 3300000>;
		pinctrl-names = "pmx_fm_active","pmx_fm_suspend";
		pinctrl-0 = <&fm_int_active &fm_status_int_active &fm_rst_active>;
		pinctrl-1 = <&fm_int_suspend &fm_status_int_suspend &fm_rst_suspend>;
		silabs,reset-gpio = <&tlmm 39 0>;
		silabs,int-gpio = <&tlmm 38 0>;
		silabs,status-gpio = <&tlmm 78 0>;
		#address-cells = <0>;
		interrupts = <0 1>;
		#interrupt-cells = <1>;
		interrupt-map-mask = <0xffffffff>;
		interrupt-map = <
				  0 &tlmm 38 2
				  1 &tlmm 78 1
				>;
		interrupt-names = "silabs_fm_int", "silabs_fm_status_int";
	};
*/
};

&i2c_8 { /* BLSP2 QUP2 */
	nq@28 {
		compatible = "nxp,pn54x";
		reg = <0x28>;
		nfc,irq_gpio = <&tlmm 9 0x00>;
		nfc,ven_gpio = <&tlmm 12 0x00>;
		nfc,firm_gpio = <&pm8994_gpios 7 0x00>;
		qcom,nq-clkreq = <&pm8994_gpios 10 0x00>;
		interrupt-parent = <&tlmm>;
		qcom,clk-src = "BBCLK2";
		interrupts = <9 0>;
		interrupt-names = "nfc_irq";
		pinctrl-names = "nfc_active", "nfc_suspend";
		pinctrl-0 = <&nfc_int_active &nfc_disable_active>;
		pinctrl-1 = <&nfc_int_suspend &nfc_disable_suspend>;
		clocks = <&clock_gcc clk_bb_clk2_pin>;
		clock-names = "ref_clk";
	};

// add by ztemt start
		ir_remote_i_three@11 {
			status = "okay";
			reg = <0x11>;
			compatible = "uei,i_three";
			vdd-supply = <&pm8994_l17>;
		};
    rohm@38 {
		compatible = "rohm,bh1745";
		reg = <0x38>;
		vdd-supply = <&pm8994_l29>;
	  vio-supply = <&pm8994_s4>;
		bh1745,tp_moudle_count = <3>;
		/*[module_id] [golden judge] r[0] r[1] g[0] g[1] b[0] b[1]*/
		bh1745,cal_data0 = "0","198","495","1179","127","215","0","0",
		/*[white judge] r[0] r[1] g[0] g[1] b[0] b[1]*/
		"230","94","49","346","321","0","0",
		/*[balck judge] r[0] r[1] g[0] g[1] b[0] b[1]*/
		"235","97","164","404","860","0","0";
		/*[module_id] [golden judge] r[0] r[1] g[0] g[1] b[0] b[1]*/
		bh1745,cal_data1 = "1","242","1565","932","9035","8607","0","0",
		/*[white judge] r[0] r[1] g[0] g[1] b[0] b[1]*/
		"189","146","88","598","533","0","0",
		/*[balck judge] r[0] r[1] g[0] g[1] b[0] b[1]*/
		"1040","1911","310","11509","9976","0","0";
		/*[module_id] [golden judge] r[0] r[1] g[0] g[1] b[0] b[1]*/
		bh1745,cal_data2 = "2","199","488","274","2283","2068","0","0",
		/*[white judge] r[0] r[1] g[0] g[1] b[0] b[1]*/
		"194","216","113","886","821","0","0",
		/*[balck judge] r[0] r[1] g[0] g[1] b[0] b[1]*/
		"396","2301","547","13243","12687","0","0";
	};

	hall_device_i2c_adapter@e2 {
		status = "okay";
		reg = <0x2e>;
		compatible = "zte,hall_pair_out";
		interrupt-parent = <&tlmm>;
		hall_device,s-irq-gpio = <&tlmm 124 0x00>;
		hall_device,n-irq-gpio = <&tlmm 38 0x00>;
		vdd-supply = <&pm8994_s4>;
		hall_device,vdd-max= <1950000>;
		hall_device,vdd-min=  <1750000>;
		pinctrl-names = "hall_device_int_active","hall_device_int_suspend";
		pinctrl-0 = <&hall_device_int_active>;
		pinctrl-1 = <&hall_device_int_suspend>;
		};
	txc@1e {
		compatible = "txc,pa224";
		reg = <0x1e>;
		interrupt-parent = <&tlmm>;
		interrupts = <122 0x2>;
		vdd-supply = <&pm8994_l29>;
		vio-supply = <&pm8994_s4>;
		txc,irq-gpio = <&tlmm 122 0x2002>;
		txc,vdd-always-on = <0>;
		txc,ps_threshold_low = <30>;
		txc,ps_threshold_high = <120>;
		pinctrl-names = "pa224_default","pa224_sleep";
		pinctrl-0 = <&pa224_default>;
		pinctrl-1 =<&pa224_sleep>;
		};
	pressure_dev@50 {
		status = "okay";
		reg = <0x50>;
		compatible = "nubia,pressure_sensor_ndt";
		pressure,fw-name = "pressure-dev-ndt.bin";
		pressure,support_smart_key = <0>;
		pressure_key,type = <1>;
		pressure_key,code = <256>;
		pressure_key,wakeup_code = <257>;
		interrupt-parent = <&tlmm>;
		pressure,reset-pin = <&tlmm 96 0x00>;
		pressure,vlps-pin = <&tlmm 78 0x00>;
		pressure,irq-pin = <&tlmm 78 0x2003>;
		pinctrl-names = "pressure_ndt_default","pressure_ndt_sleep";
		pinctrl-0 = <&pressure_ndt_default>;
		pinctrl-1 = <&pressure_ndt_sleep>;
	};
	// add by ztemt end
};
&wil6210 {
	status = "ok";
};
